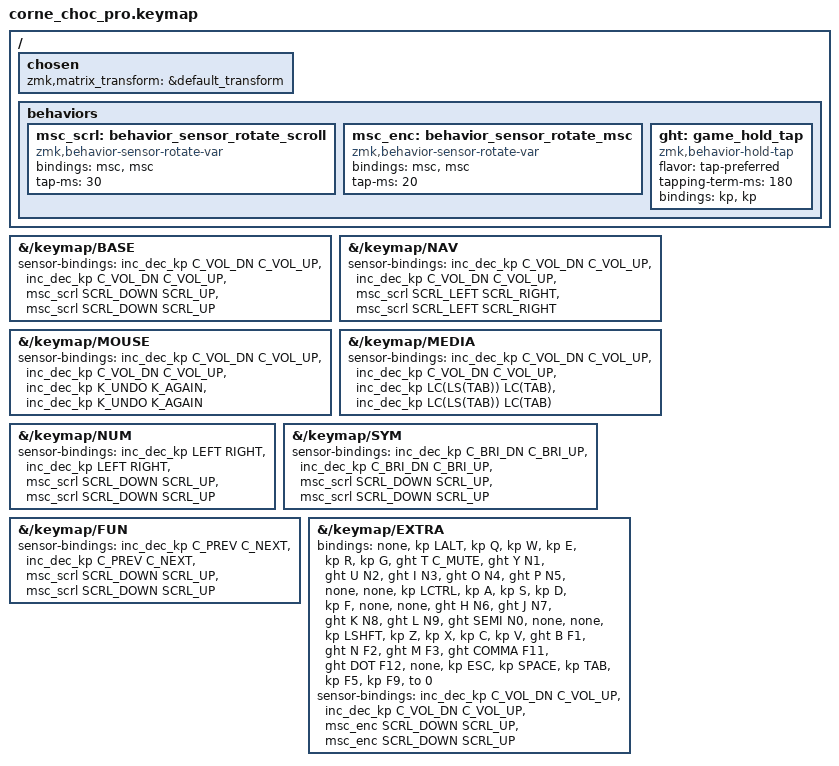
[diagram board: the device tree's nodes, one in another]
// Copyright 2025 Manna Harbour
// https://github.com/manna-harbour/miryoku

// SMOOTH scrolling build.  Requires in the .conf:
//   CONFIG_ZMK_POINTING_SMOOTH_SCROLLING=y   (and CONFIG_ZMK_POINTING=y)
// NOTCH scrolling build (consistent across Linux + Mac, keeps gaming clean).
// Requires in the .conf:  CONFIG_ZMK_POINTING=y  and NO smooth-scrolling line
// (CONFIG_ZMK_POINTING_SMOOTH_SCROLLING must be OFF / removed).
// In notch mode each unit is a normal wheel notch, so keep this value at 1.
// Scroll SPEED is set by the dwell time below (msc_scrl's tap-ms): raise it for
// faster document scrolling, lower it for slower.
// Must be defined BEFORE the includes to beat pointing.h's default.
#define ZMK_POINTING_DEFAULT_SCRL_VAL 1

#include "../miryoku/custom_config.h"
#include "../miryoku/mapping/46/corne_v4.h"
#include "../miryoku/miryoku.dtsi"

/ {
  chosen {
    zmk,matrix_transform = &default_transform;
  };

  // Encoder -> mouse scroll.  &msc scrolls at a rate WHILE held, so more dwell
  // (tap-ms) per detent = more scroll.  Two variants:
  //   msc_scrl : long dwell  -> fast document scrolling
  //   msc_enc  : short dwell -> ~one notch, for gaming weapon swap
  // Raise msc_scrl's tap-ms if documents still scroll too slowly.
  behaviors {
    msc_scrl: behavior_sensor_rotate_scroll {
      compatible = "zmk,behavior-sensor-rotate-var";
      #sensor-binding-cells = <2>;
      bindings = <&msc>, <&msc>;
      tap-ms = <30>;
    };
    msc_enc: behavior_sensor_rotate_msc {
      compatible = "zmk,behavior-sensor-rotate-var";
      #sensor-binding-cells = <2>;
      bindings = <&msc>, <&msc>;
      tap-ms = <20>;
    };
    // Gaming hold-tap for the right-hand keys: tap = number/F-key, hold = letter.
    // tap-preferred means a quick tap is ALWAYS the tap (never misfires to the
    // letter from fast presses); you only get the letter by deliberately holding.
    // Usage is <hold> <tap>, e.g. &ght Y N1 = tap 1, hold Y.
    ght: game_hold_tap {
      compatible = "zmk,behavior-hold-tap";
      #binding-cells = <2>;
      flavor = "tap-preferred";
      tapping-term-ms = <180>;
      bindings = <&kp>, <&kp>;
    };
  };
};

// --- Encoders (rotation only; the EC11 push is NOT wired on this board) ---
// Sensor order = <left_ex1  left_ex2  right_ex1  right_ex2>.
// Ben has one encoder per half, so both slots of a half get the same binding.
//
// Ergonomic pairing: LEFT-thumb layers free the RIGHT hand for the right knob;
// RIGHT-thumb layers free the LEFT hand for the left knob.
//
//   Layer    Left knob            Right knob
//   Base     Volume               vertical scroll
//   Nav      Volume               horizontal scroll   (hold Space)
//   Mouse    Volume               Undo / Redo         (hold Tab)
//   Media    Volume               Tab cycle           (hold Esc)
//   Num      Left / Right arrows  scroll              (hold Bspc)
//   Sym      Display brightness   scroll              (hold Enter)
//   Fun      Track prev/next      scroll              (hold Del)
//   Extra    Volume               weapon swap (scroll)
// Undo/Redo use dedicated HID keys (K_UNDO/K_AGAIN) - same as the Nav/Button
// clipboard keys, so no Ctrl-vs-Cmd issue.  Tab-cycle uses Ctrl+Tab (both OSes).
&{/keymap/BASE} {
    sensor-bindings
        = <&inc_dec_kp C_VOL_DN C_VOL_UP>   // left  -> Volume
        , <&inc_dec_kp C_VOL_DN C_VOL_UP>
        , <&msc_scrl SCRL_DOWN SCRL_UP>   // right -> vertical scroll
        , <&msc_scrl SCRL_DOWN SCRL_UP>
        ;
};
&{/keymap/NAV} {                             // right -> horizontal scroll
    sensor-bindings
        = <&inc_dec_kp C_VOL_DN C_VOL_UP>
        , <&inc_dec_kp C_VOL_DN C_VOL_UP>
        , <&msc_scrl SCRL_LEFT SCRL_RIGHT>
        , <&msc_scrl SCRL_LEFT SCRL_RIGHT>
        ;
};
&{/keymap/MOUSE} {                           // right -> Undo / Redo (dedicated keys)
    sensor-bindings
        = <&inc_dec_kp C_VOL_DN C_VOL_UP>
        , <&inc_dec_kp C_VOL_DN C_VOL_UP>
        , <&inc_dec_kp K_UNDO K_AGAIN>
        , <&inc_dec_kp K_UNDO K_AGAIN>
        ;
};
&{/keymap/MEDIA} {                           // right -> Tab cycle
    sensor-bindings
        = <&inc_dec_kp C_VOL_DN C_VOL_UP>
        , <&inc_dec_kp C_VOL_DN C_VOL_UP>
        , <&inc_dec_kp LC(LS(TAB)) LC(TAB)>
        , <&inc_dec_kp LC(LS(TAB)) LC(TAB)>
        ;
};
&{/keymap/NUM} {                             // left -> Left/Right arrows (also seeks video)
    sensor-bindings
        = <&inc_dec_kp LEFT RIGHT>
        , <&inc_dec_kp LEFT RIGHT>
        , <&msc_scrl SCRL_DOWN SCRL_UP>
        , <&msc_scrl SCRL_DOWN SCRL_UP>
        ;
};
&{/keymap/SYM} {                             // left -> Display brightness
    sensor-bindings
        = <&inc_dec_kp C_BRI_DN C_BRI_UP>
        , <&inc_dec_kp C_BRI_DN C_BRI_UP>
        , <&msc_scrl SCRL_DOWN SCRL_UP>
        , <&msc_scrl SCRL_DOWN SCRL_UP>
        ;
};
&{/keymap/FUN} {                             // left -> Track prev/next
    sensor-bindings
        = <&inc_dec_kp C_PREV C_NEXT>
        , <&inc_dec_kp C_PREV C_NEXT>
        , <&msc_scrl SCRL_DOWN SCRL_UP>
        , <&msc_scrl SCRL_DOWN SCRL_UP>
        ;
};

// --- EXTRA layer repurposed as a FPS gaming layer -------------------------
// Left hand = instant FPS controls (movement cluster never touched).
// Right hand (off the mouse) uses hold-taps to reach the whole alphabet:
// TAP = number / F-key, HOLD = the letter.  &ght is <hold> <tap>.
// Knob buttons: left = G (grenade); right = Mute/T (tap Mute, hold T).
// Right knob turn = weapon swap.
//
//   ALT  Q W E R  | G  Mu/T |  1/Y  2/U  3/I  4/O  5/P
//   CTRL A S D F  |         |  6/H  7/J  8/K  9/L  0/;
//   SHFT Z X C V  |         | F1/B F2/N F3/M F11/, F12/.
//              ESC SPACE TAB  |  F5  F9  to-Base
&{/keymap/EXTRA} {
    bindings = <
        &none &kp LALT &kp Q &kp W &kp E &kp R   &kp G &ght T C_MUTE     &ght Y N1 &ght U N2 &ght I N3 &ght O N4 &ght P N5 &none
        &none &kp LCTRL &kp A &kp S &kp D &kp F   &none &none     &ght H N6 &ght J N7 &ght K N8 &ght L N9 &ght SEMI N0 &none
        &none &kp LSHFT &kp Z &kp X &kp C &kp V             &ght B F1 &ght N F2 &ght M F3 &ght COMMA F11 &ght DOT F12 &none
        &kp ESC &kp SPACE &kp TAB   &kp F5 &kp F9 &to 0
    >;
    // Left knob stays Volume; right knob becomes scroll wheel = weapon swap.
    // Flip SCRL_DOWN/SCRL_UP if next/previous feels reversed in-game.
    sensor-bindings
        = <&inc_dec_kp C_VOL_DN C_VOL_UP>
        , <&inc_dec_kp C_VOL_DN C_VOL_UP>
        , <&msc_enc SCRL_DOWN SCRL_UP>
        , <&msc_enc SCRL_DOWN SCRL_UP>
        ;
};
